# SCR_TC3xx register map
Vendor: Infineon; File version: 1.0
Registers are 8-bit, read-write, reset 0x0 unless marked. A register's access mark holds for its fields unless they carry their own. Offsets are from the block's base; [hi:lo] are bit positions; {n}, {i} and the like mark numbered series; 'fields as' and 'values as' point back to an identical list.

## SCR_PORT — SCR General purpose I/O ports SCR_P00 (P33.0-P33.7) and SCR_P01 (P34.1, P33.8-P33.15)
Base 0x00040000
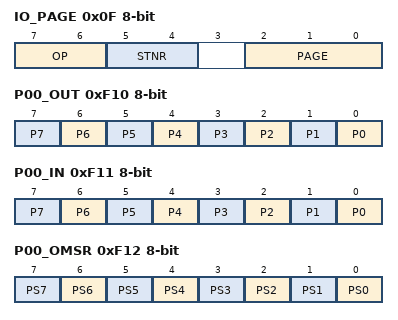
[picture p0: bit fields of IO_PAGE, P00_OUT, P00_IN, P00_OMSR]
0x0F IO_PAGE — Page Register for Port SFRs (SFR 0x8F, RMAP 0)
  [7:6] OP — Operation. [w]
    0=PAGE_MANUAL0 (Manual page mode. The value of STNR is ignored and PAGE is directly written.); 1=PAGE_MANUAL1 (Manual page mode. The value of STNR is ignored and PAGE is directly written); 2=PAGE_SAVE (New page programming with automatic page saving. The value written to the bit positions of PAGE is stored. In parallel, the former contents of PAGE are saved in the storage bit field STx indicated by STNR.); 3=PAGE_RESTORE (Automatic restore page action. The value written to the bit positions PAGE is ignored and instead, PAGE is overwritten by the contents of the storage bit field STx indicated by STNR.)
  [5:4] STNR — Storage Number. This number indicates which storage bitfield is the target of the operation defined by bit OP. If OP = 10B, the contents of PAGE are saved in STx before being overwritten with the new value. If OP = 11B, the contents of PAGE are overwritten by the contents of STx. The value written to bitfield PAGE is ignored. [w]
    {v}=MOD_ST{v} (ST{v} is selected) (v=0..3)
  [2:0] PAGE — Page Bits. When written, the value indicates the new page address. When read, the value indicates the currently active page = addr[y:x+1]. … [rw]
    0=ST0 is selected; 1=ST1 is selected; 7=ST1 is selected
0xF10 P00_OUT — Port P00 Output Register (SFR 0x90, IO_PAGE page 0, RMAP 0)
  [all] fields
    0=THE_OUTPUT_LEVEL_OF_PN_M_IS_0; 1=THE_OUTPUT_LEVEL_OF_PN_M_IS_1
  [n] P{n} (n=0..7) — Port n Output Bit {n}. This bit determines the level at the output pin Pn.m if the output is selected as GPIO output. Pn.m can also be set or cleared by control bits of the SCR_P0n_OMSR, SCR_P0n_OMCR or SCR_P0n_OMTR registers. [rwh]
0xF11 P00_IN ro — Port P00 Input Register (SFR 0x91, IO_PAGE page 0, RMAP 0)
  [all] fields
    0=THE_INPUT_LEVEL_OF_PN_M_IS_0; 1=THE_INPUT_LEVEL_OF_PN_M_IS_1
  [n] P{n} (n=0..7) — Port n Input Bit {n}. This bit reflects the level at the input pin Pn.m. [rh]
0xF12 P00_OMSR wo — Port P00 Output Modification Set Register (SFR 0x92, IO_PAGE page 0, RMAP 0)
  [all] fields
    0=NO_OPERATION; 1=SETS_PN_OUT_PM
  [n] PS{n} (n=0..7) — Port n Set Bit {n}. Setting this bit will set the corresponding bit in the port output register SCR_Pn_OUT. Read as 0. [w]
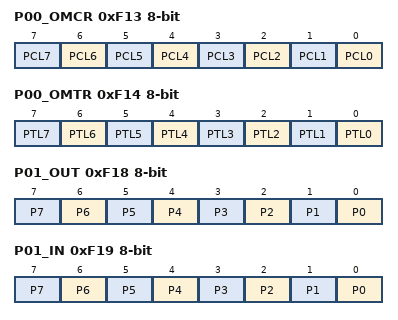
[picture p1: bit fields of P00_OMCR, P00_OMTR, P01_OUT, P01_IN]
0xF13 P00_OMCR wo — Port P00 Output Modification Clear Register (SFR 0x93, IO_PAGE page 0, RMAP 0)
  [all] fields
    0=NO_OPERATION; 1=CLEARS_SCR_PN_OUT_PM
  [n] PCL{n} (n=0..7) — Port n Clear Bit {n}. Setting this bit will clear the corresponding bit in the port output register SCR_Pn_OUT. Read as 0. [w]
0xF14 P00_OMTR wo — Port P00 Output Modification Toggle Register (SFR 0x94, IO_PAGE page 0, RMAP 0)
  [all] fields
    0=NO_OPERATION; 1=TOGGLES_SCR_PN_OUT_PM
  [n] PTL{n} (n=0..7) — Port n Toggle Bit {n}. Setting this bit will toggle the corresponding bit in the port output register SCR_Pn_OUT. Read as 0. [w]
0xF18 P01_OUT — Port P01 Output Register (SFR 0x98, IO_PAGE page 0, RMAP 0)
  fields as P00_OUT
0xF19 P01_IN ro — Port P01 Input Register (SFR 0x99, IO_PAGE page 0, RMAP 0)
  fields as P00_IN
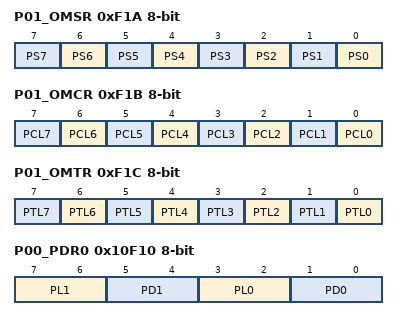
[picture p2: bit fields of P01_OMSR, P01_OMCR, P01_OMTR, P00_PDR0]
0xF1A P01_OMSR wo — Port P01 Output Modification Set Register (SFR 0x9A, IO_PAGE page 0, RMAP 0)
  fields as P00_OMSR
0xF1B P01_OMCR wo — Port P01 Output Modification Clear Register (SFR 0x9B, IO_PAGE page 0, RMAP 0)
  fields as P00_OMCR
0xF1C P01_OMTR wo — Port P01 Output Modification Toggle Register (SFR 0x9C, IO_PAGE page 0, RMAP 0)
  fields as P00_OMTR
{0x8F10+i} P00_IOCR{i} (i=0..7) — Port P00 Input/Output Control Register {i} (SFR {0x90+i}, IO_PAGE page 1, RMAP 0)
  [7:3] PC — Port Control for Port n Pin k. This bit field determines the Port n line k functionality according to the coding table (see Table "PCx_Coding"). … [rw]
    16=PP_GPO; 31=OD_ALT_FUNC7
{0x8F18+i} P01_IOCR{i} (i=0..7) — Port P01 Input/Output Control Register {i} (SFR {0x98+i}, IO_PAGE page 1, RMAP 0)
  fields as P00_IOCR0
0x10F10 P00_PDR0 — Port P00 Pad Driver Mode 0 Register (SFR 0x90, IO_PAGE page 2, RMAP 0)
  [7:6] PL1 — Pad Level Selection for Port n Pin 1. [rw]
  [5:4] PD1 — Pad Driver Mode for Port n Pin 1. [rw]
  [3:2] PL0 — Pad Level Selection for Port n Pin 0. [rw]
  [1:0] PD0 — Pad Driver Mode for Port n Pin 0. [rw]
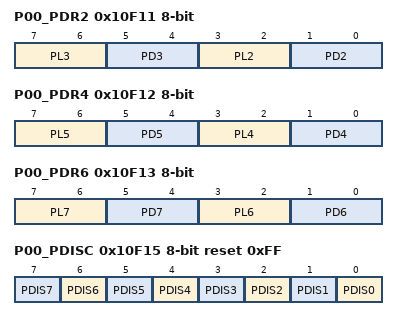
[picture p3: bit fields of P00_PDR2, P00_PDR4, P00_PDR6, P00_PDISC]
0x10F11 P00_PDR2 — Port P00 Pad Driver Mode 2 Register (SFR 0x91, IO_PAGE page 2, RMAP 0)
  [7:6] PL3 — Pad Level Selection for Port n Pin 3. [rw]
  [5:4] PD3 — Pad Driver Mode for Port n Pin 3. [rw]
  [3:2] PL2 — Pad Level Selection for Port n Pin 2. [rw]
  [1:0] PD2 — Pad Driver Mode for Port n Pin 2. [rw]
0x10F12 P00_PDR4 — Port P00 Pad Driver Mode 4 Register (SFR 0x92, IO_PAGE page 2, RMAP 0)
  [7:6] PL5 — Pad Level Selection for Port n Pin 5. [rw]
  [5:4] PD5 — Pad Driver Mode for Port n Pin 5. [rw]
  [3:2] PL4 — Pad Level Selection for Port n Pin 4. [rw]
  [1:0] PD4 — Pad Driver Mode for Port n Pin 4. [rw]
0x10F13 P00_PDR6 — Port P00 Pad Driver Mode 6 Register (SFR 0x93, IO_PAGE page 2, RMAP 0)
  [7:6] PL7 — Pad Level Selection for Port n Pin 7. [rw]
  [5:4] PD7 — Pad Driver Mode for Port n Pin 7. [rw]
  [3:2] PL6 — Pad Level Selection for Port n Pin 6. [rw]
  [1:0] PD6 — Pad Driver Mode for Port n Pin 6. [rw]
0x10F15 P00_PDISC reset 0xFF — Port P00 Pin Function Decision Control Register (SFR 0x95, IO_PAGE page 2, RMAP 0)
  [all] fields
    0=PAD_PN_M_IS_ENABLED; 1=PAD_PN_M_IS_DISABLED
  [n] PDIS{n} (n=0..7) — Pin Function Decision Control for Pin {n}. This bit selects the function of the port pad. [rw]
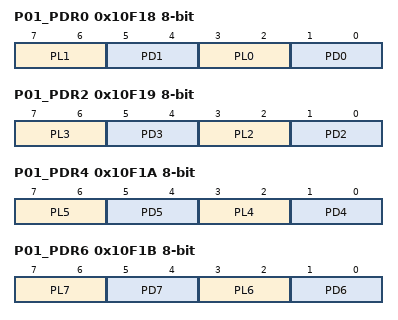
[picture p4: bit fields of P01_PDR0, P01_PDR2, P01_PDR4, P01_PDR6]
0x10F18 P01_PDR0 — Port P01 Pad Driver Mode 0 Register (SFR 0x98, IO_PAGE page 2, RMAP 0)
  fields as P00_PDR0
0x10F19 P01_PDR2 — Port P01 Pad Driver Mode 2 Register (SFR 0x99, IO_PAGE page 2, RMAP 0)
  fields as P00_PDR2
0x10F1A P01_PDR4 — Port P01 Pad Driver Mode 4 Register (SFR 0x9A, IO_PAGE page 2, RMAP 0)
  fields as P00_PDR4
0x10F1B P01_PDR6 — Port P01 Pad Driver Mode 6 Register (SFR 0x9B, IO_PAGE page 2, RMAP 0)
  fields as P00_PDR6
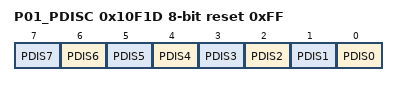
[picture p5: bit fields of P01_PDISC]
0x10F1D P01_PDISC reset 0xFF — Port P01 Pin Function Decision Control Register (SFR 0x9D, IO_PAGE page 2, RMAP 0)
  fields as P00_PDISC
